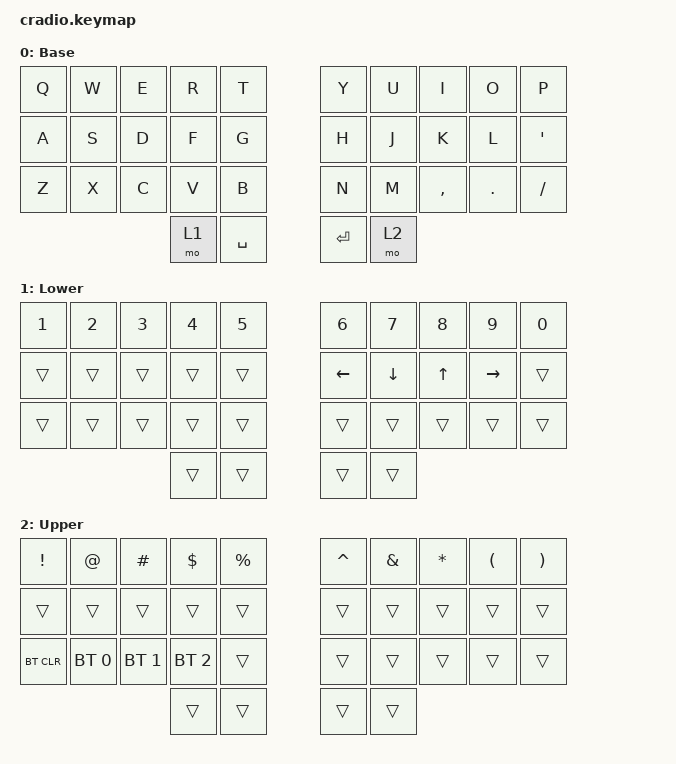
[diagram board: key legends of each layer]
// Copyright (c) 2022 The ZMK Contributors
// SPDX-License-Identifier: MIT

#include <behaviors.dtsi>
#include <dt-bindings/zmk/keys.h>
#include <dt-bindings/zmk/bt.h>

/ {
    keymap {
        compatible = "zmk,keymap";

        default_layer {
            display-name = "Base";
            bindings = 
                &kp Q &kp W &kp E &kp R &kp T &kp Y &kp U &kp I &kp O &kp P
                &kp A &kp S &kp D &kp F &kp G &kp H &kp J &kp K &kp L &kp SQT
                &kp Z &kp X &kp C &kp V &kp B &kp N &kp M &kp COMMA &kp DOT &kp FSLH
                &mo 1 &kp SPACE &kp RET &mo 2
            >;
        };

        lower_layer {
            display-name = "Lower";
            bindings = 
                &kp N1 &kp N2 &kp N3 &kp N4 &kp N5 &kp N6 &kp N7 &kp N8 &kp N9 &kp N0
                &trans &trans &trans &trans &trans &kp LEFT &kp DOWN &kp UP &kp RIGHT &trans
                &trans &trans &trans &trans &trans &trans &trans &trans &trans &trans
                &trans &trans &trans &trans
            >;
        };

        upper_layer {
            display-name = "Upper";
            bindings = 
                &kp EXCL &kp AT &kp HASH &kp DLLR &kp PRCNT &kp CARET &kp AMPS &kp STAR &kp LPAR &kp RPAR
                &trans &trans &trans &trans &trans &trans &trans &trans &trans &trans
                &bt BT_CLR &bt BT_SEL 0 &bt BT_SEL 1 &bt BT_SEL 2 &trans &trans &trans &trans &trans &trans
                &trans &trans &trans &trans
            >;
        };

        extra1 {
            display-name = "Extra1";
            status = "reserved";
        };

        extra2 {
            display-name = "Extra2";
            status = "reserved";
        };
    };
};
